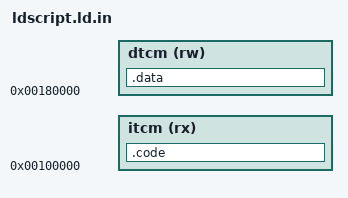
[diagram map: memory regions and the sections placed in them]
#include <liblwriscv/g_lwriscv_config.h>

OUTPUT_ARCH( "riscv" )
ENTRY(startup)
MEMORY {
    dtcm (rw) : ORIGIN = 0x0000000000180000, LENGTH = LWRISCV_DMEM_SIZE
    itcm (rx) : ORIGIN = 0x0000000000100000, LENGTH = LWRISCV_IMEM_SIZE
}
SECTIONS
{
  .code :
  {
      *(.text.startup)
      *(.text.trapEntry)
      *(.text.sspCheckFailHook)
      *.a(.text .text.*)
      *.a(.rodata .rodata.* .srodata .srodata.*)
      *(.text .text.*)
      *(.rodata .rodata.* .srodata .srodata.*)
      . = ALIGN(256);
  } > itcm
  .data :
  {
    *.a(.data .data.* .sdata. .sdata.*)
    *(.data .data.* .sdata .sdata.*)
    *.a(.bss .bss.* .sbss*)
    *(.bss .bss.* .sbss*)
    . = ALIGN(256);
    . = ALIGN(16);
    *liblwriscv.a:(.data.liblwriscv.ssp_scpdma_buf);
    _liblwriscv_stack_top = . ;
    . += 6400  ;
    _liblwriscv_stack_bottom = . ;
  } > dtcm
}
